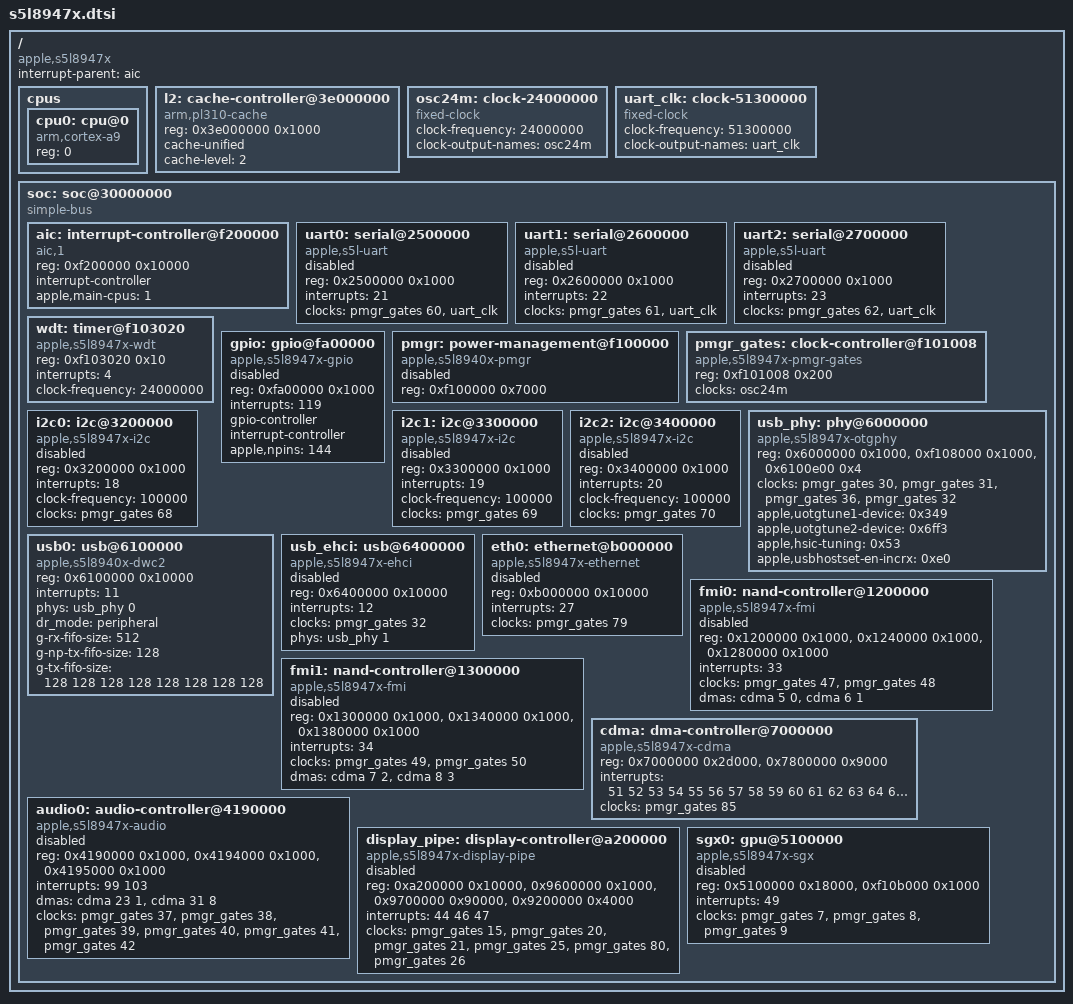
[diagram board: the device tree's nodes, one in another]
// SPDX-License-Identifier: GPL-2.0-only
/*
 * S5L8947X SoC Device Tree Include
 */

#include <dt-bindings/gpio/gpio.h>
#include <dt-bindings/interrupt-controller/irq.h>

/ {
	#address-cells = <1>;
	#size-cells = <1>;
	interrupt-parent = <&aic>;
	compatible = "apple,s5l8947x", "apple,s5l8940x";

	cpus {
		#address-cells = <1>;
		#size-cells = <0>;

		cpu0: cpu@0 {
			device_type = "cpu";
			compatible = "arm,cortex-a9";
			reg = <0>;
		};
	};

	l2: cache-controller@3e000000 {
		compatible = "arm,pl310-cache";
		reg = <0x3e000000 0x1000>;
		cache-unified;
		cache-level = <2>;
		/*
		 * 16 ways x 32 KB. Prefetching measured slower (256 KB sequential
		 * read 1843 -> 1246 MB/s), so the prefetch bits stay off; the
		 * tag and data latencies are the hardware defaults.
		 */
	};

	osc24m: clock-24000000 {
		compatible = "fixed-clock";
		#clock-cells = <0>;
		clock-frequency = <24000000>;
		clock-output-names = "osc24m";
	};

	/*
	 * UART baud clock, a PMGR peripheral clock rather than the 24 MHz
	 * oscillator: timing long transmits and the Bluetooth controller's
	 * accepted baud window both put it at 51.3 MHz. It only stays there
	 * because every CPU performance state keeps the same peripheral
	 * divider.
	 */
	uart_clk: clock-51300000 {
		compatible = "fixed-clock";
		#clock-cells = <0>;
		clock-frequency = <51300000>;
		clock-output-names = "uart_clk";
	};

	soc: soc@30000000 {
		compatible = "simple-bus";
		#address-cells = <1>;
		#size-cells = <1>;
		ranges = <0x0 0x30000000 0x10000000>;

		aic: interrupt-controller@f200000 {
			compatible = "aic,1", "apple,aic1";
			reg = <0xf200000 0x10000>;
			interrupt-controller;
			#interrupt-cells = <1>;
			#address-cells = <0>;
			apple,main-cpus = <1>;
		};

		uart0: serial@2500000 {
			compatible = "apple,s5l-uart", "samsung,s3c6400-uart";
			reg = <0x2500000 0x1000>;
			interrupts = <21>;
			clocks = <&pmgr_gates 60>, <&uart_clk>;
			clock-names = "uart", "clk_uart_baud0";
			status = "disabled";
		};

		/* System / IR remote MCU link */
		uart1: serial@2600000 {
			compatible = "apple,s5l-uart", "samsung,s3c6400-uart";
			reg = <0x2600000 0x1000>;
			interrupts = <22>;
			clocks = <&pmgr_gates 61>, <&uart_clk>;
			clock-names = "uart", "clk_uart_baud0";
			status = "disabled";
		};

		/* Bluetooth HCI link */
		uart2: serial@2700000 {
			compatible = "apple,s5l-uart", "samsung,s3c6400-uart";
			reg = <0x2700000 0x1000>;
			interrupts = <23>;
			clocks = <&pmgr_gates 62>, <&uart_clk>;
			clock-names = "uart", "clk_uart_baud0";
			status = "disabled";
		};

		wdt: timer@f103020 {
			compatible = "apple,s5l8947x-wdt", "apple,s5l8940x-wdt-timer";
			reg = <0xf103020 0x10>;
			interrupts = <4>;
			clock-frequency = <24000000>;
			status = "okay";
		};

		/* 18 ports of 8 pins; pin N is port N / 8, bit N % 8 */
		gpio: gpio@fa00000 {
			compatible = "apple,s5l8947x-gpio", "apple,s5l8940x-gpio";
			reg = <0xfa00000 0x1000>;
			interrupts = <119>;
			gpio-controller;
			#gpio-cells = <2>;
			interrupt-controller;
			#interrupt-cells = <2>;
			apple,npins = <144>;
			status = "disabled";
		};

		pmgr: power-management@f100000 {
			compatible = "apple,s5l8940x-pmgr", "syscon";
			reg = <0xf100000 0x7000>;
			status = "disabled";
		};

		pmgr_gates: clock-controller@f101008 {
			compatible = "apple,s5l8947x-pmgr-gates";
			reg = <0xf101008 0x200>;
			clocks = <&osc24m>;
			#clock-cells = <1>;
		};

		i2c0: i2c@3200000 {
			compatible = "apple,s5l8947x-i2c", "apple,s5l8940x-i2c";
			reg = <0x3200000 0x1000>;
			interrupts = <18>;
			clock-frequency = <100000>;
			clocks = <&pmgr_gates 68>;
			clock-names = "i2c";
			#address-cells = <1>;
			#size-cells = <0>;
			status = "disabled";
		};

		i2c1: i2c@3300000 {
			compatible = "apple,s5l8947x-i2c", "apple,s5l8940x-i2c";
			reg = <0x3300000 0x1000>;
			interrupts = <19>;
			clock-frequency = <100000>;
			clocks = <&pmgr_gates 69>;
			clock-names = "i2c";
			#address-cells = <1>;
			#size-cells = <0>;
			status = "disabled";
		};

		i2c2: i2c@3400000 {
			compatible = "apple,s5l8947x-i2c", "apple,s5l8940x-i2c";
			reg = <0x3400000 0x1000>;
			interrupts = <20>;
			clock-frequency = <100000>;
			clocks = <&pmgr_gates 70>;
			clock-names = "i2c";
			#address-cells = <1>;
			#size-cells = <0>;
			status = "disabled";
		};

		usb_phy: phy@6000000 {
			compatible = "apple,s5l8947x-otgphy", "apple,s5l-usb-phy";
			reg = <0x6000000 0x1000>,
			      <0xf108000 0x1000>,
			      <0x6100e00 0x4>;
			#phy-cells = <1>;
			clocks = <&pmgr_gates 30>, <&pmgr_gates 31>,
				 <&pmgr_gates 36>, <&pmgr_gates 32>;
			clock-names = "uperf", "otg", "reg", "host";
			apple,uotgtune1-device = <0x349>;
			apple,uotgtune2-device = <0x6ff3>;
			apple,hsic-tuning = <0x53>;
			apple,usbhostset-en-incrx = <0xe0>;
			status = "okay";
		};

		usb0: usb@6100000 {
			compatible = "apple,s5l8940x-dwc2", "snps,dwc2";
			reg = <0x6100000 0x10000>;
			interrupts = <11>;
			phys = <&usb_phy 0>;
			phy-names = "usb2-phy";
			dr_mode = "peripheral";
			g-rx-fifo-size = <512>;
			g-np-tx-fifo-size = <128>;
			g-tx-fifo-size = <128 128 128 128 128 128 128 128>;
			status = "okay";
		};

		/*
		 * EHCI host of the USB complex. Port 1 is the USB 2.0 host PHY,
		 * port 2 is the HSIC link to the on-board Wi-Fi chip.
		 */
		usb_ehci: usb@6400000 {
			compatible = "apple,s5l8947x-ehci", "generic-ehci";
			reg = <0x6400000 0x10000>;
			interrupts = <12>;
			clocks = <&pmgr_gates 32>;
			phys = <&usb_phy 1>;
			phy-names = "usb";
			status = "disabled";
		};

		eth0: ethernet@b000000 {
			compatible = "apple,s5l8947x-ethernet";
			reg = <0xb000000 0x10000>;
			interrupts = <27>;
			clocks = <&pmgr_gates 79>;
			status = "disabled";
		};

		/*
		 * Flash memory interface, two channels.  Each has a host block
		 * (transfer setup and the data / metadata FIFOs), a sequencer
		 * block (chip enables, commands, addresses) and an ECC block.
		 * The FIFOs are drained by central DMA channels 5/6 (FMI0) and
		 * 7/8 (FMI1) on request lines 0/1 and 2/3.
		 */
		fmi0: nand-controller@1200000 {
			compatible = "apple,s5l8947x-fmi";
			reg = <0x1200000 0x1000>,
			      <0x1240000 0x1000>,
			      <0x1280000 0x1000>;
			reg-names = "host", "seq", "ecc";
			interrupts = <33>;
			clocks = <&pmgr_gates 47>, <&pmgr_gates 48>;
			dmas = <&cdma 5 0>, <&cdma 6 1>;
			dma-names = "data", "meta";
			status = "disabled";
		};

		fmi1: nand-controller@1300000 {
			compatible = "apple,s5l8947x-fmi";
			reg = <0x1300000 0x1000>,
			      <0x1340000 0x1000>,
			      <0x1380000 0x1000>;
			reg-names = "host", "seq", "ecc";
			interrupts = <34>;
			clocks = <&pmgr_gates 49>, <&pmgr_gates 50>;
			dmas = <&cdma 7 2>, <&cdma 8 3>;
			dma-names = "data", "meta";
			status = "disabled";
		};

		/*
		 * Central DMA.  One interrupt per channel, in channel order:
		 * entry N is the interrupt of channel N + 1.  Clients name a
		 * channel (1..42) and a request line; the S/PDIF transmitter
		 * is served by channel 31 (IRQ 81), request line 8.
		 */
		cdma: dma-controller@7000000 {
			compatible = "apple,s5l8947x-cdma";
			reg = <0x7000000 0x2d000>,
			      <0x7800000 0x9000>;
			interrupts = <51 52 53 54 55 56 57 58 59 60 61 62 63 64
				      65 66 67 68 69 70 71 72 73 74 75 76 77 78
				      79 80 81 82 83 84 85 86 87 88 89 90 91 92>;
			clocks = <&pmgr_gates 85>;
			#dma-cells = <2>;
			status = "okay";
		};

		audio0: audio-controller@4190000 {
			compatible = "apple,s5l8947x-audio";
			reg = <0x4190000 0x1000>,
			      <0x4194000 0x1000>,
			      <0x4195000 0x1000>;
			reg-names = "i2s0", "spdif", "i2s-master";
			interrupts = <99 103>;
			dmas = <&cdma 23 1>, <&cdma 31 8>;
			dma-names = "hdmi", "optical";
			clocks = <&pmgr_gates 37>, <&pmgr_gates 38>,
				 <&pmgr_gates 39>, <&pmgr_gates 40>,
				 <&pmgr_gates 41>, <&pmgr_gates 42>;
			status = "disabled";
		};

		display_pipe: display-controller@a200000 {
			compatible = "apple,s5l8947x-display-pipe";
			reg = <0xa200000 0x10000>,
			      <0x9600000 0x1000>,
			      <0x9700000 0x90000>,
			      <0x9200000 0x4000>;
			reg-names = "rgbout", "out", "hdmi", "scaler";
			interrupts = <44 46 47>;
			clocks = <&pmgr_gates 15>, <&pmgr_gates 20>,
				 <&pmgr_gates 21>, <&pmgr_gates 25>,
				 <&pmgr_gates 80>, <&pmgr_gates 26>;
			clock-names = "hperf-rt-a", "rgbout-a", "hperf-rt-b",
				      "rgbout-b", "hdmi", "scaler";
			status = "disabled";
		};

		sgx0: gpu@5100000 {
			compatible = "apple,s5l8947x-sgx", "img,sgx543";
			reg = <0x5100000 0x18000>, <0xf10b000 0x1000>;
			interrupts = <49>;
			clocks = <&pmgr_gates 7>, <&pmgr_gates 8>, <&pmgr_gates 9>;
			status = "disabled";
		};
	};
};
